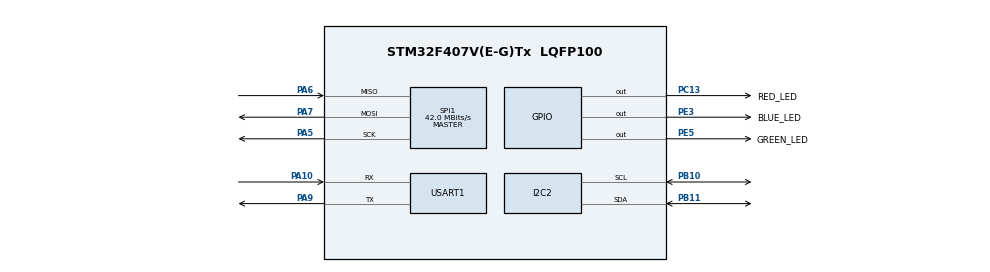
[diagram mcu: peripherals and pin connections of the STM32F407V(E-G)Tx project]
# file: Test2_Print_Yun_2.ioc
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Mcu.Family=STM32F4
Mcu.Name=STM32F407V(E-G)Tx
Mcu.Package=LQFP100
NVIC.PriorityGroup=NVIC_PRIORITYGROUP_4
NVIC.USART1_IRQn=true\:0\:0\:false\:false\:true\:true\:true
PA10.Mode=Asynchronous
PA10.Signal=USART1_RX
PA13.Mode=Serial_Wire
PA13.Signal=SYS_JTMS-SWDIO
PA14.Mode=Serial_Wire
PA14.Signal=SYS_JTCK-SWCLK
PA5.Mode=Full_Duplex_Master
PA5.Signal=SPI1_SCK
PA6.Mode=Full_Duplex_Master
PA6.Signal=SPI1_MISO
PA7.Mode=Full_Duplex_Master
PA7.Signal=SPI1_MOSI
PA9.Mode=Asynchronous
PA9.Signal=USART1_TX
PB10.Mode=I2C
PB10.Signal=I2C2_SCL
PB11.Mode=I2C
PB11.Signal=I2C2_SDA
PC13-ANTI_TAMP.GPIO_Label=RED_LED
PC13-ANTI_TAMP.Signal=GPIO_Output
PC14-OSC32_IN.Mode=LSE-External-Oscillator
PC14-OSC32_IN.Signal=RCC_OSC32_IN
PC15-OSC32_OUT.Mode=LSE-External-Oscillator
PC15-OSC32_OUT.Signal=RCC_OSC32_OUT
PE3.GPIO_Label=BLUE_LED
PE3.Signal=GPIO_Output
PE5.GPIO_Label=GREEN_LED
PE5.PinState=GPIO_PIN_SET
PE5.Signal=GPIO_Output
PH0-OSC_IN.Mode=HSE-External-Oscillator
PH0-OSC_IN.Signal=RCC_OSC_IN
PH1-OSC_OUT.Mode=HSE-External-Oscillator
PH1-OSC_OUT.Signal=RCC_OSC_OUT
ProjectManager.HeapSize=0x200
ProjectManager.StackSize=0x400
ProjectManager.TargetToolchain=STM32CubeIDE
RCC.48MHZClocksFreq_Value=84000000
RCC.AHBFreq_Value=168000000
RCC.APB1CLKDivider=RCC_HCLK_DIV4
RCC.APB1Freq_Value=42000000
RCC.APB1TimFreq_Value=84000000
RCC.APB2CLKDivider=RCC_HCLK_DIV2
RCC.APB2Freq_Value=84000000
RCC.APB2TimFreq_Value=168000000
RCC.CortexFreq_Value=168000000
RCC.HCLKFreq_Value=168000000
RCC.HSE_VALUE=8000000
RCC.HSI_VALUE=16000000
RCC.PLLM=8
RCC.PLLN=168
RCC.SYSCLKFreq_VALUE=168000000
RCC.SYSCLKSource=RCC_SYSCLKSOURCE_PLLCLK
RCC.VCOOutputFreq_Value=336000000
SPI1.CalculateBaudRate=42.0 MBits/s
SPI1.Direction=SPI_DIRECTION_2LINES
SPI1.Mode=SPI_MODE_MASTER
SPI1.VirtualType=VM_MASTER
USART1.VirtualMode=VM_ASYNC
board=custom

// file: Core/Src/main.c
/* USER CODE BEGIN Header */
/**
  ******************************************************************************
  * @file           : main.c
  * @brief          : Main program body
  ******************************************************************************
  * @attention
  *
  * <h2><center>&copy; Copyright (c) 2021 STMicroelectronics.
  * All rights reserved.</center></h2>
  *
  * This software component is licensed by ST under BSD 3-Clause license,
  * the "License"; You may not use this file except in compliance with the
  * License. You may obtain a copy of the License at:
  *                        opensource.org/licenses/BSD-3-Clause
  *
  ******************************************************************************
  */
/* USER CODE END Header */
#include "main.h"
#include "i2c.h"
#include "spi.h"
#include "usart.h"
#include "gpio.h"

/* USER CODE BEGIN PV */
uint8_t Buf_5[5] = {0};
/* USER CODE END PV */

void SystemClock_Config(void);

int main(void)
{

  /* MCU Configuration--------------------------------------------------------*/

  /* Reset of all peripherals, Initializes the Flash interface and the Systick. */
  HAL_Init();

  /* Configure the system clock */
  SystemClock_Config();

  /* Initialize all configured peripherals */
  MX_GPIO_Init();
  MX_USART1_UART_Init();
  MX_I2C2_Init();
  MX_SPI1_Init();
  /* USER CODE BEGIN 2 */
  printf("Hello World!\n");
  DEBUG_PRINT(WORD_OK, "初始化GPIO和USART成功");
  HAL_UART_Receive_IT(&huart1, Buf_5, sizeof(Buf_5));
  /* USER CODE END 2 */

  /* Infinite loop */
  while (1)
  {

  }
}

void SystemClock_Config(void)
{
  LL_FLASH_SetLatency(LL_FLASH_LATENCY_5);
  while(LL_FLASH_GetLatency()!= LL_FLASH_LATENCY_5)
  {
  }
  LL_PWR_SetRegulVoltageScaling(LL_PWR_REGU_VOLTAGE_SCALE1);
  LL_RCC_HSI_SetCalibTrimming(16);
  LL_RCC_HSI_Enable();

   /* Wait till HSI is ready */
  while(LL_RCC_HSI_IsReady() != 1)
  {

  }
  LL_RCC_PLL_ConfigDomain_SYS(LL_RCC_PLLSOURCE_HSI, LL_RCC_PLLM_DIV_8, 168, LL_RCC_PLLP_DIV_2);
  LL_RCC_PLL_Enable();

   /* Wait till PLL is ready */
  while(LL_RCC_PLL_IsReady() != 1)
  {

  }
  LL_RCC_SetAHBPrescaler(LL_RCC_SYSCLK_DIV_1);
  LL_RCC_SetAPB1Prescaler(LL_RCC_APB1_DIV_4);
  LL_RCC_SetAPB2Prescaler(LL_RCC_APB2_DIV_2);
  LL_RCC_SetSysClkSource(LL_RCC_SYS_CLKSOURCE_PLL);

   /* Wait till System clock is ready */
  while(LL_RCC_GetSysClkSource() != LL_RCC_SYS_CLKSOURCE_STATUS_PLL)
  {

  }
  LL_SetSystemCoreClock(168000000);

   /* Update the time base */
  if (HAL_InitTick (TICK_INT_PRIORITY) != HAL_OK)
  {
    Error_Handler();
  }
}

/* USER CODE BEGIN 4 */
void HAL_UART_RxCpltCallback(UART_HandleTypeDef *huart)
{
	printf("%s\r\n", Buf_5);
	printf("接收到数据\r\n");
	HAL_UART_Receive_IT(&huart1, Buf_5, sizeof(Buf_5));
}
/* USER CODE END 4 */

void Error_Handler(void)
{
  __disable_irq();
  while (1)
  {
  }
}

/************************ (C) COPYRIGHT STMicroelectronics *****END OF FILE****/
